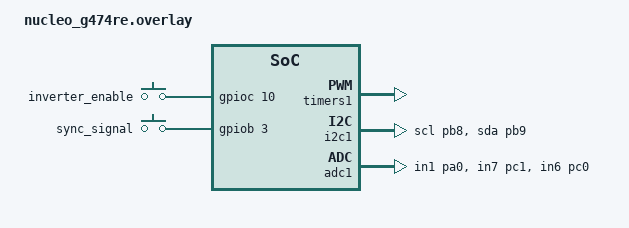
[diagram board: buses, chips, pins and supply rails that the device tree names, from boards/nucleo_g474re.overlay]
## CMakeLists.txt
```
cmake_minimum_required(VERSION 3.13.1)
find_package(Zephyr REQUIRED HINTS $ENV{ZEPHYR_BASE})
project(step_foc)

target_sources(app PRIVATE src/foc_driver.c)
target_sources(app PRIVATE src/foc_svm.c)
target_sources(app PRIVATE src/main.c)
target_sources(app PRIVATE src/foc_nodes.c)
target_sources(app PRIVATE src/observer_node.c)
target_sources(app PRIVATE src/foc_scope.c)
```

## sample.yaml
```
sample:
  name: Secure telemetry pipeline FoC motor control sample using position observer
tests:
  test:
    tags: step
```

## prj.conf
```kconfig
CONFIG_PRINTK=y
CONFIG_SERIAL=y
CONFIG_CBPRINTF_FP_SUPPORT=y

CONFIG_SHELL=y
CONFIG_SHELL_HISTORY=y
CONFIG_SHELL_VT100_COLORS=y

CONFIG_LOG=y
CONFIG_LOG_DEFAULT_LEVEL=4
CONFIG_LOG_MODE_DEFERRED=y

CONFIG_STEP=y
CONFIG_STEP_PROC_MGR_POLL_RATE=0
CONFIG_STEP_POOL_SIZE=4096

# necessary to use CMSIS-DSP
CONFIG_NEWLIB_LIBC=y
CONFIG_CMSIS_DSP=y
CONFIG_CMSIS_DSP_FASTMATH=y
CONFIG_CMSIS_DSP_CONTROLLER=y
CONFIG_CMSIS_DSP_TABLES=y

# enable PWM
CONFIG_PWM=y

# also the I2C:
CONFIG_I2C=y

# also the ADC for current measurement:
CONFIG_ADC=y
CONFIG_ADC_ASYNC=y
```

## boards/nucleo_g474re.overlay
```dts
/*
 * SPDX-License-Identifier: Apache-2.0
 *
 * Copyright (c) 2022 Linaro
 */

 #include <dt-bindings/pwm/pwm.h>
 #include <dt-bindings/adc/adc.h>

/ {
	gpio_enable {
		compatible = "gpio-keys";
		inverter_enable: button {
			label = "inverter_enable";
			gpios = <&gpioc 10 GPIO_ACTIVE_HIGH>,
                    <&gpioc 11 GPIO_ACTIVE_HIGH>,
                    <&gpioc 12 GPIO_ACTIVE_HIGH>;
		};
	};

	gpio_sync {
		compatible = "gpio-keys";
		sync_signal: button {
			label = "sync_signal";
			gpios = <&gpiob 3 GPIO_ACTIVE_HIGH>,
					<&gpiob 5 GPIO_ACTIVE_HIGH>;

		};
	};
};
 
/* Set PWM that are attached to the IHM07 dev board's power stage */
&timers1 {
     status = "okay";
 
     inverter_pwm: pwm {
         status = "okay";
         pinctrl-0 = <&tim1_ch1_pa8 &tim1_ch2_pa9 &tim1_ch3_pa10 &tim1_ch4_pa11>; 
         pinctrl-names = "default";
     };
};

&i2c1 {
	pinctrl-0 = <&i2c1_scl_pb8 &i2c1_sda_pb9>;
	pinctrl-names = "default";
	status = "okay";
};

&adc1 {
	pinctrl-0 = <&adc1_in1_pa0 &adc1_in7_pc1 &adc1_in6_pc0>;
	pinctrl-names = "default";
	status = "okay";
};
```

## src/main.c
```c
/*
 * Copyright (c) 2022 Linaro
 *
 * SPDX-License-Identifier: Apache-2.0
 */

#include <zephyr.h>
#include <stdlib.h>
#include <step/step.h>
#include <step/proc_mgr.h>
#include <shell/shell.h>
#include "foc_driver.h"
#include "foc_nodes.h"
#include "observer_node.h"
#include "foc_scope.h"

/* Default values given by HT2205 motor */
#define SAMPLE_MOTOR_POLE_PAIRS 		7.0f 
#define SAMPLE_ADC_TO_AMPS_RATIO 		0.00159608f /* (ADC_Vref / (Gain  * ADC_MAX * Shunt Resistance)) */
#define SAMPLE_MOTOR_PHASE_INDUCTANCE	0.00145f /* Henry */	
#define SAMPLE_MOTOR_PHASE_RESISTANCE   7.1f	 /* Ohms */
#define SAMPLE_MOTOR_BACK_EMF_CONSTANT  0.19f	 /* V/rad/s */
#define SAMPLE_MOTOR_FLUX_LINKAGE		(SAMPLE_MOTOR_BACK_EMF_CONSTANT / (2.0f * SAMPLE_MOTOR_POLE_PAIRS))
#define SAMPLE_MOTOR_OBSERVER_GAIN	    1.0f  
 
static float motor_vq;
static float motor_vd;

void on_foc_measurement(struct step_measurement *mes)
{
	/* just update the desired voltage, data publish is handled by
	 * by the driver automatically
	 */
	struct foc_controller_payload *p = mes->payload;
	p->cmd.voltage_q = motor_vq;
	p->cmd.voltage_d = motor_vd;
}

void main(void)
{	
	int rc = 0;
	uint32_t handle, obs_handle;

	motor_vq = 0.0f;
	motor_vd = 0.0f;

	/* configure the observer */
	motor_observer_node_conf.motor_phase_inductance = SAMPLE_MOTOR_PHASE_INDUCTANCE;
	motor_observer_node_conf.motor_phase_resistance = SAMPLE_MOTOR_PHASE_RESISTANCE;
	motor_observer_node_conf.motor_flux_linkage = SAMPLE_MOTOR_FLUX_LINKAGE;
	motor_observer_node_conf.observer_gain = SAMPLE_MOTOR_OBSERVER_GAIN;
	motor_observer_node_conf.motor_poles = SAMPLE_MOTOR_POLE_PAIRS * 2.0f;

	/* initialize the foc driver first */
	rc = foc_driver_initialize(SAMPLE_ADC_TO_AMPS_RATIO,
							motor_observer_node_conf.motor_poles / 2.0f,
							on_foc_measurement);
	if (rc) {
		printk("foc driver init failed!\n");
		return;
	}

	/* Then register the FoC processing pipeline */
	rc = step_pm_register(foc_node_chain, 0, &handle);
	if (rc) {
		printk("Node registration failed!\n");
		return;
	}

	/* And the rotor position observer node: */
	rc = step_pm_register(observer_node_chain, 0, &obs_handle);
	if (rc) {
		printk("Node registration failed!\n");
		return;
	}

}

static int step_foc_cmd_set(const struct shell *shell, size_t argc, char **argv)
{
	if (argc != 3) {
		return -EINVAL;
	}

	motor_vq = strtof(argv[1], NULL);
	motor_vd = strtof(argv[2], NULL);
	return 0;
}

static int step_foc_cmd_motor_phy(const struct shell *shell, size_t argc, char **argv)
{
	if (argc != 5) {
		return -EINVAL;
	}

	float poles_temp = strtof(argv[3], NULL);

	if((int)poles_temp == 0) {
		return -EINVAL;
	}

	motor_observer_node_conf.motor_phase_inductance = strtof(argv[1], NULL);
	motor_observer_node_conf.motor_phase_resistance = strtof(argv[2], NULL);
	motor_observer_node_conf.motor_poles = poles_temp;
	motor_observer_node_conf.motor_flux_linkage = strtof(argv[4], NULL) / motor_observer_node_conf.motor_poles;
	return 0;
}

static int step_foc_cmd_observer_gain(const struct shell *shell, size_t argc, char **argv)
{
	if (argc != 2) {
		return -EINVAL;
	}

	float observer_temp = strtof(argv[1], NULL);
	if(observer_temp < 0.0f) {
		return -EINVAL;
	}

	motor_observer_node_conf.observer_gain = observer_temp;

	return 0;
}

static int step_foc_cmd_align(const struct shell *shell, size_t argc, char **argv)
{
	return foc_driver_set_encoder_offset();
}

static int step_foc_cmd_scope_on(const struct shell *shell, size_t argc, char **argv)
{
	foc_scope_enable();
	return 0;
}

static int step_foc_cmd_scope_off(const struct shell *shell, size_t argc, char **argv)
{
	foc_scope_disable();
	return 0;
}

/* Subcommand array for "step_foc" (level 1). */
SHELL_STATIC_SUBCMD_SET_CREATE(
	sub_step_foc,
	SHELL_CMD(set, NULL, "Set voltage d-q vector to control the motor between -1 and +1", step_foc_cmd_set),
	SHELL_CMD(align, NULL, "Align rotor and calibrate its position sensor", step_foc_cmd_align),
	SHELL_CMD(motor_phy, NULL, "Set motor physical parameters inductance, resistance, Back EMF constant and number of Poles", step_foc_cmd_motor_phy),
	SHELL_CMD(observer_gain, NULL, "Sets the observer gain, it must be > 0", step_foc_cmd_observer_gain),
	SHELL_CMD(scope, NULL, "Enables FoC scope data streaming", step_foc_cmd_scope_on),	
	SHELL_CMD(noscope, NULL, "Disables FoC scope data streaming", step_foc_cmd_scope_off),	
	SHELL_SUBCMD_SET_END
	);

/* Root command "step_foc" (level 0). */
SHELL_CMD_REGISTER(step_foc, &sub_step_foc, "Secure telemetry pipeline FoC sample commands", NULL);
```

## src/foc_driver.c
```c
/*
 * Copyright (c) 2022 Linaro
 *
 * SPDX-License-Identifier: Apache-2.0
 */

#include <arm_math.h>
#include <string.h>
#include <zephyr.h>
#include <device.h>
#include <drivers/i2c.h>
#include <drivers/pwm.h>
#include <drivers/gpio.h>
#include <drivers/adc.h>
#include <drivers/counter.h>

#include <sys/printk.h>
#include <step/sample_pool.h>
#include <step/proc_mgr.h>
#include "foc_driver.h"

/** AS5600 I2C Encoder constants */
#define AS5600_SLAVE_ADDR 0x36
#define AS5600_ANGLE_REGISTER_H 0x0E
#define AS5600_PULSES_PER_REVOLUTION 4096.0f
#define AS5600_READING_MASK 0xFFF 

#define ROTOR_DRV_PAYLOAD_SZ      (sizeof(struct foc_controller_payload))
#define ROTOR_DRV_PAYLOAD_SRC_ID  (2)
#define PWM_PERIOD_NSEC 62500

/**
 * @brief Pre-populated measurement header to copy into allocated measurements.
 */
static struct step_mes_header rotor_sensor_header = {
	/* Filter word. */
	.filter = {
		.base_type = STEP_MES_TYPE_PHASE,
		.flags = {
			.data_format = STEP_MES_FORMAT_NONE,
			.encoding = STEP_MES_ENCODING_NONE,
			.compression = STEP_MES_COMPRESSION_NONE,
			.timestamp = STEP_MES_TIMESTAMP_UPTIME_MS_32,
		},
	},
	/* SI Unit word. */
	.unit = {
		.si_unit = STEP_MES_UNIT_SI_RADIAN,
		.ctype = STEP_MES_UNIT_CTYPE_IEEE754_FLOAT32,
		.scale_factor = STEP_MES_SI_SCALE_NONE,
	},
	/* Source/Len word. */
	.srclen = {
		.len = ROTOR_DRV_PAYLOAD_SZ,
		.fragment = 0,
		.sourceid = ROTOR_DRV_PAYLOAD_SRC_ID,
	}
};

/* FoC driver regulation thread */
static void foc_driver_regulation_loop(void *arg);
K_THREAD_DEFINE(reg_loop_tid, 4096,
		foc_driver_regulation_loop, NULL, NULL, NULL,
		0, 0, 0);

K_SEM_DEFINE(foc_trigger, 0, 1);

static void adc_work_handler(struct k_work *work);
K_WORK_DEFINE(adc_wq, adc_work_handler);

static enum adc_action foc_adc_measurement_handler(const struct device *dev,
						 const struct adc_sequence *sequence,
						 uint16_t sampling_index);

static float foc_adc_to_amperes_ratio = 1.0f;
static uint8_t sample_iabc_index = 0;
static int16_t adc_offsets[2] = {0,};
static int16_t adc_iabc_buffer[2];

static const struct adc_sequence_options iabc_options = {
	.interval_us = 0,
	.callback = foc_adc_measurement_handler,
	.extra_samplings = 0,
};

static const struct adc_sequence ia_sequence = {
	.options 	 = &iabc_options,
    .channels    = BIT(1),
    .buffer      = &adc_iabc_buffer[0],
    .buffer_size = sizeof(int16_t),
    .resolution  = 12,
};

static const struct adc_sequence ib_sequence = {
	.options 	 = &iabc_options,
    .channels    = BIT(7),
    .buffer      = &adc_iabc_buffer[1],
    .buffer_size = sizeof(int16_t),
    .resolution  = 12,
};

static const struct adc_channel_cfg ia_channel_cfg = {
	.gain             = ADC_GAIN_1,
	.reference        = ADC_REF_INTERNAL,
	.acquisition_time = ADC_ACQ_TIME_DEFAULT,
	.channel_id       = 1,
};

static const struct adc_channel_cfg ib_channel_cfg = {
	.gain             = ADC_GAIN_1,
	.reference        = ADC_REF_INTERNAL,
	.acquisition_time = ADC_ACQ_TIME_DEFAULT,
	.channel_id       = 7,
};

static const float encoder_to_degrees_ratio = (360.0f) / AS5600_PULSES_PER_REVOLUTION;
static const uint32_t pwm_period_half = (PWM_PERIOD_NSEC / 4);

static foc_measurement_callback_t user_callback;
static float pole_pairs;

static struct {
	uint16_t raw;
	uint16_t zero_offset;
} encoder_reading;

static const struct device *inverter_pwm = DEVICE_DT_GET(DT_NODELABEL(inverter_pwm));
static const struct device *encoder_i2c = DEVICE_DT_GET(DT_NODELABEL(i2c1));
static const struct device *current_sensors_adc = DEVICE_DT_GET(DT_NODELABEL(adc1));

static struct gpio_dt_spec enable_u = GPIO_DT_SPEC_GET_BY_IDX(DT_NODELABEL(inverter_enable),gpios,0);
static struct gpio_dt_spec enable_v = GPIO_DT_SPEC_GET_BY_IDX(DT_NODELABEL(inverter_enable),gpios,1);
static struct gpio_dt_spec enable_w = GPIO_DT_SPEC_GET_BY_IDX(DT_NODELABEL(inverter_enable),gpios,2);
static struct gpio_dt_spec sync_signal = GPIO_DT_SPEC_GET_BY_IDX(DT_NODELABEL(sync_signal),gpios,1);
static struct gpio_dt_spec instrumentation_signal = GPIO_DT_SPEC_GET_BY_IDX(DT_NODELABEL(sync_signal),gpios,0);

static struct gpio_callback pwm_sync_callback;
static struct step_measurement *bldc_measurement;

static uint16_t foc_driver_read_encoder(void)
{
	uint16_t raw;
	uint8_t read_data[2] = {0,0};
	uint8_t angle_reg = AS5600_ANGLE_REGISTER_H;

	/* gets the raw position from encoder */
	int err = i2c_write_read(encoder_i2c, 
						AS5600_SLAVE_ADDR,
						&angle_reg,
						1,
						&read_data,
						sizeof(read_data));

	if(err) {
		return 0xFFFF;
	}

	raw = ((uint16_t)read_data[0] << 8) | read_data[1];

	/* wrap to its maximum value */
	if(raw > AS5600_PULSES_PER_REVOLUTION - 1) {
		raw = AS5600_PULSES_PER_REVOLUTION - 1 ;
	}

	return raw;
}

static void foc_driver_get_rotor_position(struct step_measurement * rotor_measurement)
{
	struct foc_controller_payload *p = rotor_measurement->payload;
	struct foc_feeback_sensor_data *fdbk = &p->state;

	fdbk->motor_pole_pairs = pole_pairs;

	/* update the encoder reading */
	uint16_t counts = foc_driver_read_encoder();

	/* keeps a ZOH (Zero Order Hold) by just accepting valid measurements to 
	 * reduce position reading distortion
	 */
	if(counts <= (AS5600_PULSES_PER_REVOLUTION - 1)) {
		/* valid readings, update the encoder */
		encoder_reading.raw = counts;
	}

	/* make encoder measures to radians for mech and electrical angle */
	fdbk->rotor_position = (float)((encoder_reading.raw - encoder_reading.zero_offset) &
						 AS5600_READING_MASK) * encoder_to_degrees_ratio;
	fdbk->e_rotor_position = fdbk->motor_pole_pairs * fdbk->rotor_position;

	p->timestamp = k_uptime_get_32();
}

static void foc_driver_get_abc_currents(struct step_measurement * rotor_measurement)
{
	struct foc_controller_payload *p = rotor_measurement->payload;

	p->state.i_abc[0] = (float)(adc_offsets[0] - adc_iabc_buffer[0]) * foc_adc_to_amperes_ratio;
	p->state.i_abc[1] = (float)(adc_offsets[1] - adc_iabc_buffer[1]) * foc_adc_to_amperes_ratio; 

	/* reconstruct the third current */
	p->state.i_abc[2] = -(p->state.i_abc[0] + p->state.i_abc[1]);
}

static void foc_capture_isr(const struct device *port,
					struct gpio_callback *cb,
					gpio_port_pins_t pins)
{
	sample_iabc_index = 0;
	k_work_submit(&adc_wq);
}

static enum adc_action foc_adc_measurement_handler(const struct device *dev,
						 const struct adc_sequence *sequence,
						 uint16_t sampling_index)
{	
	sample_iabc_index++;
	k_work_submit(&adc_wq);
	return ADC_ACTION_FINISH;
}

static void adc_work_handler(struct k_work *work) 
{
	// if (!sample_iabc_index) {
	// 	adc_read_async(current_sensors_adc, &ia_sequence, NULL);
	// } else if (sample_iabc_index == 1) {
	// 	adc_read_async(current_sensors_adc, &ib_sequence, NULL);
	// } else {
		k_sem_give(&foc_trigger);
	// }
}

static void foc_driver_regulation_loop(void *arg)
{	
	int mcnt;
	bldc_measurement = step_sp_alloc(ROTOR_DRV_PAYLOAD_SZ);

	for(;;) {
		k_sem_take(&foc_trigger, K_FOREVER);

		gpio_pin_set_dt(&instrumentation_signal, 1);
		//foc_driver_get_rotor_position(bldc_measurement);
		foc_driver_get_abc_currents(bldc_measurement);

		if(user_callback) {
			user_callback(bldc_measurement);
		}

		/* fill measurements information before publishing: */
		bldc_measurement->header.filter_bits = rotor_sensor_header.filter_bits;
		bldc_measurement->header.unit_bits = rotor_sensor_header.unit_bits;
		bldc_measurement->header.srclen_bits = rotor_sensor_header.srclen_bits;

		/* publish sensor measurement to be processed by the waiters
		* in that case, FoC pipeline would be one of the waiters 
		*/
		step_sp_put(bldc_measurement);
		step_pm_poll(&mcnt, false);
		gpio_pin_set_dt(&instrumentation_signal, 0);
	}
}

int foc_driver_initialize(float adc_to_amperes_ratio, float motor_pole_pairs, foc_measurement_callback_t cb)
{
	int rc = 0;

	user_callback = cb;
	pole_pairs = motor_pole_pairs;
	foc_adc_to_amperes_ratio = adc_to_amperes_ratio;

	encoder_reading.raw = 0;
	encoder_reading.zero_offset = 0;

	i2c_configure(encoder_i2c, I2C_MODE_MASTER | I2C_SPEED_FAST);
	foc_driver_set_duty_cycle(0.0f, 0.0f, 0.0f);

	adc_channel_setup(current_sensors_adc, &ia_channel_cfg);
	adc_channel_setup(current_sensors_adc, &ib_channel_cfg);

	gpio_pin_configure_dt(&enable_u, GPIO_OUTPUT);
	gpio_pin_configure_dt(&enable_v, GPIO_OUTPUT);
	gpio_pin_configure_dt(&enable_w, GPIO_OUTPUT);
	gpio_pin_configure_dt(&instrumentation_signal, GPIO_OUTPUT);

	gpio_pin_set_dt(&enable_u, 1);
	gpio_pin_set_dt(&enable_v, 1);
	gpio_pin_set_dt(&enable_w, 1);
	gpio_pin_set_dt(&instrumentation_signal, 0);

	/* sets the adc offsets by reading them before enabling any motor phase */
	adc_read(current_sensors_adc, &ia_sequence);
	adc_read(current_sensors_adc, &ib_sequence);
	adc_offsets[0] = adc_iabc_buffer[0];
	adc_offsets[1] = adc_iabc_buffer[1];

	gpio_pin_configure_dt(&sync_signal, GPIO_INPUT);
	gpio_pin_interrupt_configure_dt(&sync_signal, GPIO_INT_EDGE_FALLING);
	gpio_init_callback(&pwm_sync_callback, foc_capture_isr, BIT(sync_signal.pin));
	gpio_add_callback(sync_signal.port, &pwm_sync_callback);
	pwm_set(inverter_pwm, 4 , PWM_PERIOD_NSEC, pwm_period_half, 0);

	return rc;
}

int foc_driver_set_encoder_offset(void)
{
	/* align rotor each startup */
	encoder_reading.zero_offset = foc_driver_read_encoder() & AS5600_READING_MASK;

	return 0;
}

void foc_driver_set_duty_cycle(float dc_u, float dc_v, float dc_w)
{
	/* saturate the duties */
	if(dc_u > 1.0f) {
		dc_u = 1.0f;
	} else if (dc_u < 0.0f) {
		dc_u = 0.0f;
	}

	if(dc_v > 1.0f) {
		dc_v = 1.0f;
	} else if (dc_v < 0.0f) {
		dc_v = 0.0f;
	}

	if(dc_w > 1.0f) {
		dc_w = 1.0f;
	} else if (dc_w < 0.0f) {
		dc_w = 0.0f;
	}

	/* scale the duty cycle to nanoseconds */
	dc_u *= PWM_PERIOD_NSEC - 1;
	dc_v *= PWM_PERIOD_NSEC - 1;
	dc_w *= PWM_PERIOD_NSEC - 1;

	pwm_set(inverter_pwm, 1 , PWM_PERIOD_NSEC, dc_u, 0);
	pwm_set(inverter_pwm, 2 , PWM_PERIOD_NSEC, dc_v, 0);
	pwm_set(inverter_pwm, 3 , PWM_PERIOD_NSEC, dc_w, 0);
}
```

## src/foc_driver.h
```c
/*
 * Copyright (c) 2022 Linaro
 *
 * SPDX-License-Identifier: Apache-2.0
 */

#ifndef FOC_DRIVER_H__
#define FOC_DRIVER_H__

#include <step/step.h>
#include <step/measurement/measurement.h>

#ifdef __cplusplus
extern "C" {
#endif

/**
 * @brief FoC measurement reception callback:
 */
typedef void (*foc_measurement_callback_t) (struct step_measurement *mes);

/**
 * @brief FoC rotor position sensor data:
 */
struct foc_feeback_sensor_data {
	float i_abc[3];
	float i_alpha_beta[2];
	float motor_pole_pairs;
	float e_rotor_position;
	float rotor_position;
	float estimated_rotor_position;
	float dt;
};

/**
 * @brief FoC voltages flow data:
 */
struct foc_command_data {
	float voltage_q;
	float voltage_d;
	float voltage_alpha;
	float voltage_beta;
	float voltage_u;
	float voltage_v;
};

/**
 * @brief FoC data payload descriptor:
 */
struct foc_controller_payload {
	uint32_t timestamp;
	struct foc_feeback_sensor_data state;
	struct foc_command_data cmd;
};

/**
 * @brief Initializes the foc driver.
 *
 * @param adc_to_amperes_ratio board specific scale from ADC to amperes
 * 
 * @param cb user callback to be executed each measurement from motor rotor position.
 * 
 * @param motor_pole_pairs number of motor pole pairs.
 * 
 * @return int  0 on success, otherwise a negative error code.
 * 
 */
int foc_driver_initialize(float adc_to_amperes_ratio, float motor_pole_pairs, foc_measurement_callback_t cb);


/**
 * @brief Sets the 0-degree offset for the encoder
 * 
 * @return int  0 on success, otherwise a negative error code.
 * 
 */
int foc_driver_set_encoder_offset(void);

/**
 * @brief set inverter voltages based on duty cycle.
 * 
 * @param dc_u voltage to be applied to the in phase u of motor
 *
 * @param dc_v voltage to be applied to the in phase v of motor
 *
 * @param dc_v voltage to be applied to the in phase v of motor
 * 
 * @param values should be normalized between 0 and 1 
 */
void foc_driver_set_duty_cycle(float dc_u, float dc_v, float dc_w);

#ifdef __cplusplus
}
#endif

#endif /* STEP_SHELL_DRIVER_H_ */
```

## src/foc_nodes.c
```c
/*
 * Copyright (c) 2022 Linaro
 *
 * SPDX-License-Identifier: Apache-2.0
 */

#include <zephyr.h>
#include <stdio.h>
#include <logging/log.h>
#include <step/proc_mgr.h>
#include "foc_nodes.h"
#include "foc_driver.h"
#include "foc_svm.h"
#include "foc_scope.h"
#include <arm_math.h>

/**
 *  ┌───────────────┐
 *  │               │
 *  │ Rotor Sensor  │          This is the FoC pipeline created using STeP:
 *  │ (I2C)         │       1. Collect node which is trigggered by rotor position sensor driver
 *  │               │       2. Inverse Park transfor to map VQD to rotating VaplhaBeta
 *  │               │       3. Inverse Clarke transform to project ValphaBeta into 3-phase vector
 *  └──────┬────────┘       4. Inverter update node that sends 3-phase vector to the PWM driver
 *         │
 *         │                The STeP node chain is created to represent the block diagram
 *         │                below.
 *         │
 *         │
 *         │           ---------------------------------------------------
 *         │		   | FoC algorithm Node								 |						 	
 * ┌───────▼────────┐  | ┌────────────────┐            ┌───────────────┐ |       ┌────────────────┐
 * │                │  | │                │            │               │ |       │                │
 * │  Collect       │  | │ Inverse        │            │ Inverse       │ |       │ Inverter       │
 * │  Node          │  | │ Park Transform │            │ Clarke Trans. │ |       │ Update         │
 * │                ├───►│                ├────────────►               ├────────►│ Node           │
 * │  Capture       │  | │ VQD -> Vab     │            │ Vab->Vuvw     │ |       │ Vuvw-> SVPWM   │
 * │  the samples   │  | │                │            │               │ |       │                │
 * │                │  | │                │            │               │ |       │                │
 * └───────▲────────┘  | └────────────────┘            └───────────────┘ |       └────────┬───────┘
 *         │           |                                                 |                │
 *         │           |-------------------------------------------------|                │
 *         │                                                                              ▼
 *         │                                                                     ┌────────────────┐
 *  ┌──────┴────────┐                                                            │                │
 *  │               │                                                            │ Inverter       │
 *  │ Desired       │                                                            │ Driver         │
 *  │ Voltage       │                                                            │                │
 *  │ (Shell)       │                                                            │ (PWM)          │
 *  │               │                                                            │                │
 *  │               │                                                            └────────────────┘
 *  └───────────────┘
 */

/* rotor sensor align step */
int foc_align_rotor(void *cfg, uint32_t handle, uint32_t inst)
{
	/* for rotor alignment the idea is to provide the initial voltage
	 * vector with a phase of 90 degree and apply to the motor, and wait
	 * the rotor to align mechanically to that voltage applied, this will
	 * translate the stator and rotor magnetic fields are properly 90 degree
	 * aligned
	 */
	float sine;
	float cosine;
	float alpha;
	float beta;
	float inverter_duties[3];

	/* we want a voltage vector with 90 degree of phase */
	arm_sin_cos_f32(90, &sine, &cosine);

	/* use only 20% of the current capacity to avoid heating*/
	arm_inv_park_f32(0.0f,
					0.2f,
					&alpha,
					&beta,
					sine,
					cosine);

	/* convert the alpha-beta frame into SVPWM signals */
	foc_svm_set(alpha, 
			beta,
			&inverter_duties[0],
			&inverter_duties[1],
			&inverter_duties[2]);

	/* set the voltage vector to the inverter and... */
	foc_driver_set_duty_cycle(inverter_duties[0], inverter_duties[1], inverter_duties[2]);
	
	/* give a delay to the rotor align mechanically */
	k_sleep(K_MSEC(500));

	/* before releasing the voltage, sets the zero angle offset in the encoder*/
	return foc_driver_set_encoder_offset();
}

/* foc algorithm process step */
int foc_do_process(struct step_measurement *mes, uint32_t handle, uint32_t inst)
{
	struct foc_controller_payload *p = mes->payload;
	struct foc_command_data *command = &p->cmd;
	struct foc_feeback_sensor_data *feed = &p->state;
	float sine;
	float cosine;

	arm_sin_cos_f32(feed->e_rotor_position, &sine, &cosine);

	arm_inv_park_f32(command->voltage_d,
					command->voltage_q,
					&command->voltage_alpha,
					&command->voltage_beta,
					sine,
					cosine);
	
	return 0;
}

/* do SVPWM update the inverter step, the last block on FoC chain */
int foc_do_space_vector_modulation(struct step_measurement *mes, uint32_t handle, uint32_t inst)
{
	struct foc_controller_payload *p = mes->payload;
	float inverter_duties[3];

	/* convert the alpha-beta frame into SVPWM signals */
	foc_svm_set(p->cmd.voltage_alpha, 
			p->cmd.voltage_beta,
			&inverter_duties[0],
			&inverter_duties[1],
			&inverter_duties[2]);

	/* and transfer them directly to the inverter */
	foc_driver_set_duty_cycle(inverter_duties[0], inverter_duties[1], inverter_duties[2]);
	
	/* update the scope after new sample is put to the driver */
	foc_scope_data_push(p);
	
	return 0;
}

/* Processor node chain. */
struct step_node foc_node_chain_data[] = {
	/* Root processor node. */
	{
		.name = "Root sensor sample processor node",
		.filters = {
			.count = 1,
			.chain = (struct step_filter[]){
				{
					/* Phase (base type). */
					.match = STEP_MES_TYPE_PHASE,
					.ignore_mask = ~STEP_MES_MASK_FULL_TYPE,
				}
			},
		},

		/* Callbacks */
		.callbacks = {
			.init_handler = foc_align_rotor,
		},

		/* Config settings */
		.config = NULL,

		/* Point to next processor node in chain. */
		.next = &foc_node_chain_data[1]
	},

	/* Processor node 1. */
	{
		.name = "foc processing node",
		/* Callbacks */
		.callbacks = {
			.exec_handler = foc_do_process,
		},

		/* Config settings */
		.config = NULL,

		/* Point to next processor node in chain. */
		.next = &foc_node_chain_data[2]
	},

	/* Processor node 2. */
	{
		.name = "inverter update",
		/* Callbacks */
		.callbacks = {
			.exec_handler = foc_do_space_vector_modulation,
		},

		/* Config settings */
		.config = NULL,

		/* End of the chain. */
		.next = NULL
	},
};

/* Pointer to node chain. */
struct step_node *foc_node_chain = foc_node_chain_data;
```

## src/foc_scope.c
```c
#include <string.h>
#include <zephyr.h>
#include <device.h>
#include <sys/printk.h>
#include "foc_scope.h"

#define SCOPE_BUFF_SIZE 512

static bool scope_enable = false;
static struct foc_controller_payload scope_buffer[2][SCOPE_BUFF_SIZE];
static bool ping_pong_switch = false;
static uint32_t rd_buff_index = 0;
static uint32_t wr_buff_index = 0;

static void foc_scope_daemon_thread(void *arg);

/* Rotor sensor measurement thread. */
K_THREAD_DEFINE(foc_scope_tid, 8192,
		foc_scope_daemon_thread, NULL, NULL, NULL,
		0, 0, 0);

static void foc_scope_daemon_thread(void *arg)
{
    struct foc_controller_payload *next_sample;
    memset(&scope_buffer, 0, sizeof(scope_buffer));

    while(1) {
        if(scope_enable) {
            next_sample = &scope_buffer[ping_pong_switch][rd_buff_index];
            		printk("%d\t%f\t%f\t%f\t%f\t%f\t%f\t%f\t%f\t%f\t%f\t%f\t%f\t%f\n",
                        next_sample->timestamp,
                        next_sample->state.motor_pole_pairs,
                        next_sample->state.rotor_position,
                        next_sample->state.estimated_rotor_position,
                        next_sample->state.i_alpha_beta[0],
                        next_sample->state.i_alpha_beta[1],
                        next_sample->cmd.voltage_q,
                        next_sample->cmd.voltage_d,
                        next_sample->cmd.voltage_alpha,
                        next_sample->cmd.voltage_beta,
                        next_sample->state.i_abc[0],
                        next_sample->state.i_abc[1],
                        next_sample->state.i_abc[2],
                        next_sample->state.dt);
            rd_buff_index++;
            if(rd_buff_index >= SCOPE_BUFF_SIZE) {
                uint32_t key = irq_lock();
                rd_buff_index = 0;
                wr_buff_index = 0;
                ping_pong_switch ^= 1;
                irq_unlock(key);
            }
           
        } else {
            k_sleep(K_MSEC(100));
        }
    }
}

void foc_scope_enable(void)
{
    scope_enable = true;
}

void foc_scope_disable(void)
{
    scope_enable = false;
}

void foc_scope_data_push(struct foc_controller_payload *p)
{
    if(!p || wr_buff_index >= SCOPE_BUFF_SIZE) {
        return;
    }

    uint32_t key = irq_lock();
    memcpy(&scope_buffer[!ping_pong_switch][wr_buff_index],
        p,
        sizeof(*p));
    
    wr_buff_index++;
    irq_unlock(key);
}
```

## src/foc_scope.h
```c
/*
 * Copyright (c) 2022 Linaro
 *
 * SPDX-License-Identifier: Apache-2.0
 */

#include <stdbool.h>
#include "foc_driver.h"

/**
 * @brief Starts scope data streaming.
 */
void foc_scope_enable(void);

/**
 * @brief Stops scope data streaming.
 */
void foc_scope_disable(void);

/**
 * @brief Push new FoC sample to scope driver.
 * 
 * @param p pointer to a sample containing FoC data.
 * 
 * @note no action is taken if p is invalid or if the buffer is full.
 * 
 */
void foc_scope_data_push(struct foc_controller_payload *p);
```

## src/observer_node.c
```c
/*
 * Copyright (c) 2022 Linaro
 *
 * SPDX-License-Identifier: Apache-2.0
 */

#include <zephyr.h>
#include <stdio.h>
#include <logging/log.h>
#include <step/proc_mgr.h>
#include <arm_math.h>
#include <math.h>
#include "observer_node.h"
#include "foc_driver.h"

/* Squared */
#define SQUARE(x)   ((x) * (x))

/* observer may enter in NAN values */
#define IS_NAN(x)   ((x) != (x))
#define NAN_ZERO(x) (x = IS_NAN(x) ? 0.0 : x)

static const float cycle_to_sec_ratio = 1.0f / (float)CONFIG_SYS_CLOCK_HW_CYCLES_PER_SEC;
static const float rad_to_degrees_ratio = (180.0f) / PI;

static struct {
	float xt_1;
	float xt_2;
	float omega_hat;
	float last_dt;		
} bldc_observer;

int observer_initialize(void *cfg, uint32_t handle, uint32_t inst)
{
	bldc_observer.xt_1 = 0.0f;
	bldc_observer.xt_2 = 0.0f;
	bldc_observer.omega_hat = 0.0f;
	bldc_observer.last_dt = cycle_to_sec_ratio * (float)k_cycle_get_32();
    return 0;
}

int observer_estimate(struct step_measurement *mes, uint32_t handle, uint32_t inst)
{
	struct foc_controller_payload *p = mes->payload;
	struct foc_feeback_sensor_data *s = &p->state;
	struct foc_command_data *cmd = &p->cmd;

	float xt_dot_1;
	float xt_dot_2;
	float error;
	float l_stator[2];
	float r_stator[2];
	float xt_norm = 0.0f;
	float now_secs = cycle_to_sec_ratio * (float)k_cycle_get_32();
	float dt = now_secs - bldc_observer.last_dt;
	bldc_observer.last_dt = now_secs;

	/* gets the i_alpha_beta currents by doing clarke transform */
	arm_clarke_f32(s->i_abc[0], s->i_abc[1], &s->i_alpha_beta[0], &s->i_alpha_beta[1]);

	/* first, compute the stator inductance plus resistance */
	l_stator[0] = 1.5f * motor_observer_node_conf.motor_phase_inductance * s->i_alpha_beta[0];
	l_stator[1] = 1.5f * motor_observer_node_conf.motor_phase_inductance * s->i_alpha_beta[1];
	r_stator[0] = 1.5f * motor_observer_node_conf.motor_phase_resistance * s->i_alpha_beta[0];
	r_stator[1] = 1.5f * motor_observer_node_conf.motor_phase_resistance * s->i_alpha_beta[1];

	/* compute estimation error */
	error = SQUARE(motor_observer_node_conf.motor_flux_linkage) - 
		(SQUARE(bldc_observer.xt_1 - l_stator[0]) - SQUARE(bldc_observer.xt_2 - l_stator[1]));

	/* force error to be positive to speed-up the convergence */
	if(error < 0.0f) {
		error = 0.0f;
	}

	/* update the observer states */
	xt_dot_1 = -r_stator[0] + cmd->voltage_alpha + 
		motor_observer_node_conf.observer_gain * 
		(bldc_observer.xt_1 - l_stator[0]) * error;

	xt_dot_2 = -r_stator[1] + cmd->voltage_beta + 
		motor_observer_node_conf.observer_gain * 
		(bldc_observer.xt_2 - l_stator[1]) * error;

	bldc_observer.xt_1 += xt_dot_1 * dt;
	bldc_observer.xt_2 += xt_dot_2 * dt;

	NAN_ZERO(bldc_observer.xt_1);
	NAN_ZERO(bldc_observer.xt_2);

	/* prevent loss of stabillity when states gets too low in magnitude */
	arm_sqrt_f32(SQUARE(bldc_observer.xt_1) + SQUARE(bldc_observer.xt_2), &xt_norm);
	if (xt_norm < (motor_observer_node_conf.motor_flux_linkage * 0.5)) {
		bldc_observer.xt_1 *= 1.1;
		bldc_observer.xt_2 *= 1.1;
	}

	/* estimate angle using the output states from observer */
	bldc_observer.omega_hat = atan2f(bldc_observer.xt_2 - l_stator[1], 
								bldc_observer.xt_1 - l_stator[0]) *
								rad_to_degrees_ratio;
	
	s->estimated_rotor_position = bldc_observer.omega_hat;
	s->dt = dt;

	return 0;
}

/* Processor node chain. */
struct step_node observer_node_chain_data[] = {
	/* Root processor node. */
	{
		.name = "observer root node",
		.filters = {
			.count = 1,
			.chain = (struct step_filter[]){
				{
					/* Phase (base type). */
					.match = STEP_MES_TYPE_PHASE,
					.ignore_mask = ~STEP_MES_MASK_FULL_TYPE,
				}
			},
		},

		/* Callbacks */
		.callbacks = {
			.init_handler = observer_initialize,
		},

		/* Config settings */
		.config = NULL,

		/* Point to next processor node in chain. */
		.next = &observer_node_chain_data[1]
	},

	/* Processor node 1. */
	{
		.name = "observer processing node",
		/* Callbacks */
		.callbacks = {
			.exec_handler = observer_estimate,
		},

		/* Config settings */
		.config = NULL,

		/* Point to next processor node in chain. */
		.next = NULL,
	},
};

/* Pointer to node chain. */
struct step_node *observer_node_chain = observer_node_chain_data;
struct motor_observer_node_config motor_observer_node_conf = {
	.observer_gain = 0.5f,
};
```

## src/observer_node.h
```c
/*
 * Copyright (c) 2022 Linaro
 *
 * SPDX-License-Identifier: Apache-2.0
 */

#ifndef OBSERVER_NODE_H__
#define OBSERVER_NODE_H__

#include <stdlib.h>
#include <stdbool.h>
#include <step/step.h>
#include <step/node.h>
#include <step/measurement/measurement.h>

#ifdef __cplusplus
extern "C" {
#endif

struct motor_observer_node_config {
    float motor_phase_resistance;
    float motor_phase_inductance;
    float motor_flux_linkage;
    float motor_poles;
    float observer_gain;
};

extern struct step_node *observer_node_chain;
extern struct motor_observer_node_config motor_observer_node_conf;

#ifdef __cplusplus
}
#endif

#endif /* STEP_SHELL_NODES_H_ */
```
